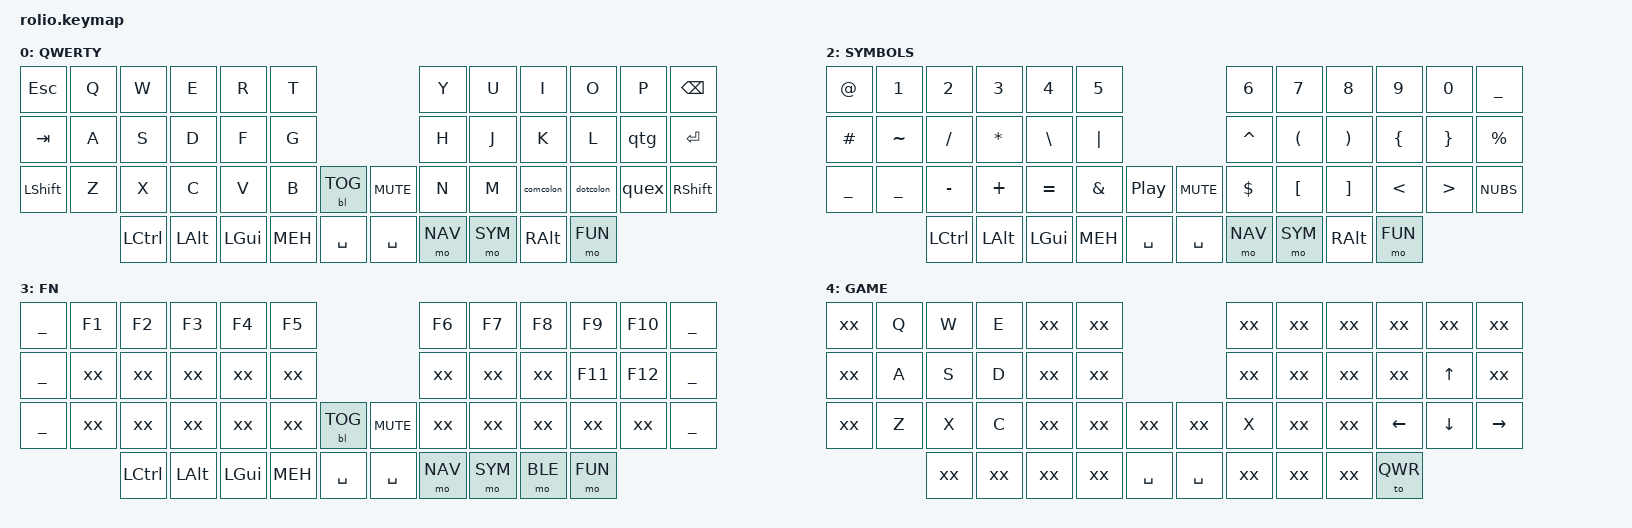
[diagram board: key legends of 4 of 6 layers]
/*
 * Copyright (c) 2023 The ZMK Contributors
 *
 * SPDX-License-Identifier: MIT
 */

#include <behaviors.dtsi>
#include <dt-bindings/zmk/keys.h>
#include <dt-bindings/zmk/bt.h>
#include <dt-bindings/zmk/outputs.h>
#include <dt-bindings/zmk/backlight.h>

#define ZMK_POINTING_DEFAULT_SCRL_VAL 100
#include <dt-bindings/zmk/pointing.h>

#include "keymap_aliases.dtsi"
#include "keymap_behaviors.dtsi"
#include "keymap_macros.dtsi"

#define QWR 0
#define NAV 1
#define SYM 2
#define FUN 3
#define HAX 4
#define BLE 5

/ {       
    keymap {
        compatible = "zmk,keymap";
        main {
            display-name = "QWERTY";
            label = "main";
            bindings = <
            /*╭───────────┬───────────┬───────────┬───────────┬───────────┬───────────╮                           ╭───────────┬───────────┬───────────┬───────────┬───────────┬───────────╮*/
                &kp ESC     &kp Q       &kp W       &kp E       &kp R       &kp T     /*                         */ &kp Y       &kp U       &kp I       &kp O       &kp P       &kp BSPC
            /*├───────────┼───────────┼───────────┼───────────┼───────────┼───────────┤                           ├───────────┼───────────┼───────────┼───────────┼───────────┼───────────┤*/
                &kp TAB     &kp A       &kp S       &kp D       &kp F       &kp G     /*                         */ &kp H       &kp J       &kp K       &kp L       &qtg        &kp RET
            /*├───────────┼───────────┼───────────┼───────────┼───────────┼───────────┤───────────╮   ╭───────────├───────────┼───────────┼───────────┼───────────┼───────────┼───────────┤*/
                &kp LSHIFT  &kp Z       &kp X       &kp C       &kp V       &kp B       &bl BL_TOG/* */ &kp MUTE    &kp N       &kp M       &comcolon   &dotcolon   &quex       &kp RSHIFT
            /*╰───────────┴───────────┼───────────┼───────────┼───────────┼───────────┼───────────╮   ╭───────────┼───────────┼───────────┼───────────┼───────────┼───────────┴───────────╯*/
                                        &kp LCTRL   &kp LALT    &kp LGUI    &kp MEH     &kp SPACE /* */ &kp SPACE   &mo NAV     &mo SYM     &kp RALT    &mo FUN
            /*                        ╰───────────┴───────────┴───────────┴───────────┤           │   │           ├───────────┴───────────┴───────────┴───────────╯                        */
            /*                                                                        ╰───────────╯   ╰───────────╯                                                                        */
            >;

            sensor-bindings = <&inc_dec_kp BRI_UP BRI_DN &inc_dec_kp VOL_UP VOL_DN>;
        };

        navigation {
            display-name = "ARROWS";
            label = "navigation";
            bindings = <
            /*╭───────────┬───────────┬───────────┬───────────┬───────────┬───────────╮                           ╭───────────┬───────────┬───────────┬───────────┬───────────┬───────────╮*/
                __          &desktop    &browser    &terminal    &editor    &chat     /*                         */ &game       &music      &d1         &d2         &d3         &kp DEL
            /*├───────────┼───────────┼───────────┼───────────┼───────────┼───────────┤                           ├───────────┼───────────┼───────────┼───────────┼───────────┼───────────┤*/
                __          xx          &kp C_PREV  &kp C_PP    &kp C_NEXT  xx        /*                         */ &kp LEFT    &kp DOWN    &kp UP      &kp RIGHT   xx          __
            /*├───────────┼───────────┼───────────┼───────────┼───────────┼───────────┤───────────╮   ╭───────────├───────────┼───────────┼───────────┼───────────┼───────────┼───────────┤*/
                __          &caps_word  &scrca      &scrc       &scrs       xx          &bl BL_TOG/* */ &kp MUTE    &kp HOME    &kp PG_DN   &kp PG_UP   &kp END     &caps_word  __
            /*╰───────────┴───────────┼───────────┼───────────┼───────────┼───────────┼───────────╮   ╭───────────┼───────────┼───────────┼───────────┼───────────┼───────────┴───────────╯*/
                                        &kp LCTRL   &kp LALT    &kp LGUI    &kp MEH     &kp SPACE /* */ &kp SPACE   &mo NAV     &mo SYM     &to HAX     &mo FUN
            /*                        ╰───────────┴───────────┴───────────┴───────────┤           │   │           ├───────────┴───────────┴───────────┴───────────╯                        */
            /*                                                                        ╰───────────╯   ╰───────────╯                                                                        */
            >;

            sensor-bindings = <&scroll_x &scroll_y>;
        };

        symbols {
            display-name = "SYMBOLS";
            label = "symbols";
            bindings = <
            /*╭───────────┬───────────┬───────────┬───────────┬───────────┬───────────╮                           ╭───────────┬───────────┬───────────┬───────────┬───────────┬───────────╮*/
                &kp AT      &kp N1      &kp N2      &kp N3      &kp N4      &kp N5    /*                         */ &kp N6      &kp N7      &kp N8      &kp N9      &kp N0      __
            /*├───────────┼───────────┼───────────┼───────────┼───────────┼───────────┤                           ├───────────┼───────────┼───────────┼───────────┼───────────┼───────────┤*/
                &kp HASH    &kp TILDE   &kp FSLH    &kp ASTRK   &kp BSLH    &kp PIPE  /*                         */ &kp CARET   &kp LPAR    &kp RPAR    &kp LBRC    &kp RBRC    &kp PRCNT
            /*├───────────┼───────────┼───────────┼───────────┼───────────┼───────────┤───────────╮   ╭───────────├───────────┼───────────┼───────────┼───────────┼───────────┼───────────┤*/
                __          &kp UNDER   &kp MINUS   &kp PLUS    &kp EQUAL   &kp AMPS    &kp C_PP  /* */ &kp MUTE    &kp DLLR    &kp LBKT    &kp RBKT    &kp LT      &kp GT      &kp NUBS
            /*╰───────────┴───────────┼───────────┼───────────┼───────────┼───────────┼───────────╮   ╭───────────┼───────────┼───────────┼───────────┼───────────┼───────────┴───────────╯*/
                                        &kp LCTRL   &kp LALT    &kp LGUI    &kp MEH     &kp SPACE /* */ &kp SPACE   &mo NAV     &mo SYM     &kp RALT    &mo FUN
            /*                        ╰───────────┴───────────┴───────────┴───────────┤           │   │           ├───────────┴───────────┴───────────┴───────────╯                        */
            /*                                                                        ╰───────────╯   ╰───────────╯                                                                        */
            >;

            sensor-bindings = <&inc_dec_kp C_NEXT C_PREV &inc_dec_kp VOL_UP VOL_DN>;
        };

        function {
            display-name = "FN";
            label = "function";
            bindings = <
            /*╭───────────┬───────────┬───────────┬───────────┬───────────┬───────────╮                           ╭───────────┬───────────┬───────────┬───────────┬───────────┬───────────╮*/
                __          &kp F1      &kp F2      &kp F3      &kp F4      &kp F5    /*                         */ &kp F6      &kp F7      &kp F8      &kp F9      &kp F10     __
            /*├───────────┼───────────┼───────────┼───────────┼───────────┼───────────┤                           ├───────────┼───────────┼───────────┼───────────┼───────────┼───────────┤*/
                __          xx          xx          xx          xx          xx        /*                         */ xx          xx          xx          &kp F11     &kp F12     __
            /*├───────────┼───────────┼───────────┼───────────┼───────────┼───────────┤───────────╮   ╭───────────├───────────┼───────────┼───────────┼───────────┼───────────┼───────────┤*/
                __          xx          xx          xx          xx          xx          &bl BL_TOG/* */ &kp MUTE    xx          xx          xx          xx          xx          __
            /*╰───────────┴───────────┼───────────┼───────────┼───────────┼───────────┼───────────╮   ╭───────────┼───────────┼───────────┼───────────┼───────────┼───────────┴───────────╯*/
                                        &kp LCTRL   &kp LALT    &kp LGUI    &kp MEH     &kp SPACE /* */ &kp SPACE   &mo NAV     &mo SYM     &mo BLE     &mo FUN
            /*                        ╰───────────┴───────────┴───────────┴───────────┤           │   │           ├───────────┴───────────┴───────────┴───────────╯                        */
            /*                                                                        ╰───────────╯   ╰───────────╯                                                                        */
            >;

            sensor-bindings = <&backlight_ctrl &backlight_ctrl>;
        };

        game {
            display-name = "GAME";
            label = "game";
            bindings = <
            /*╭───────────┬───────────┬───────────┬───────────┬───────────┬───────────╮                           ╭───────────┬───────────┬───────────┬───────────┬───────────┬───────────╮*/
                xx          &kp Q       &kp W       &kp E       xx          xx        /*                         */ xx          xx          xx          xx          xx          xx
            /*├───────────┼───────────┼───────────┼───────────┼───────────┼───────────┤                           ├───────────┼───────────┼───────────┼───────────┼───────────┼───────────┤*/
                xx          &kp A       &kp S       &kp D       xx          xx        /*                         */ xx          xx          xx          xx          &kp UP      xx
            /*├───────────┼───────────┼───────────┼───────────┼───────────┼───────────┤───────────╮   ╭───────────├───────────┼───────────┼───────────┼───────────┼───────────┼───────────┤*/
                xx          &kp Z       &kp X       &kp C       xx          xx          xx        /* */ xx          &kp X       xx          xx          &kp LEFT    &kp DOWN    &kp RIGHT
            /*╰───────────┴───────────┼───────────┼───────────┼───────────┼───────────┼───────────╮   ╭───────────┼───────────┼───────────┼───────────┼───────────┼───────────┴───────────╯*/
                                        xx          xx          xx          xx          &kp SPACE /* */ &kp SPACE   xx          xx          xx          &to QWR
            /*                        ╰───────────┴───────────┴───────────┴───────────┤           │   │           ├───────────┴───────────┴───────────┴───────────╯                        */
            /*                                                                        ╰───────────╯   ╰───────────╯                                                                        */
            >;

            sensor-bindings = <&scroll_x &scroll_y>;
        };

        reset {
            display-name = "BLE";
            label = "bluetooth";
            bindings = <
            /*╭───────────┬───────────┬───────────┬───────────┬───────────┬───────────╮                           ╭───────────┬───────────┬───────────┬───────────┬───────────┬───────────╮*/
                &bt BT_CLR  xx          xx          xx          xx          xx        /*                         */ xx          xx          xx          xx          xx          &bt BT_CLR
            /*├───────────┼───────────┼───────────┼───────────┼───────────┼───────────┤                           ├───────────┼───────────┼───────────┼───────────┼───────────┼───────────┤*/
                &output_usb BT0         BT1         BT2         BT3         BT4       /*                         */ &wpm_tog    &mod_tog    xx          xx          xx          xx
            /*├───────────┼───────────┼───────────┼───────────┼───────────┼───────────┤───────────╮   ╭───────────├───────────┼───────────┼───────────┼───────────┼───────────┼───────────┤*/
                xx          xx          xx          xx          xx          xx          xx        /* */ xx          xx          xx          xx          xx          xx          xx
            /*╰───────────┴───────────┼───────────┼───────────┼───────────┼───────────┼───────────╮   ╭───────────┼───────────┼───────────┼───────────┼───────────┼───────────┴───────────╯*/
                                        &mo BLE     xx          xx          &mo SYM     xx        /* */ xx          &mo NAV     xx          xx          &mo BLE
            /*                        ╰───────────┴───────────┴───────────┴───────────┤           │   │           ├───────────┴───────────┴───────────┴───────────╯                        */
            /*                                                                        ╰───────────╯   ╰───────────╯                                                                        */
            >;

            sensor-bindings = <&backlight_ctrl &backlight_ctrl>;
        };
        

        // Extra layers for ZMK Studio
        extra1 {
            status = "reserved";
        };
        extra2 {
            status = "reserved";
        };
        extra3 {
            status = "reserved";
        };

    };
};
